AUTOSAR XML (schema 4-2-2)
package /STELLANTIS/EPT/ASWCs
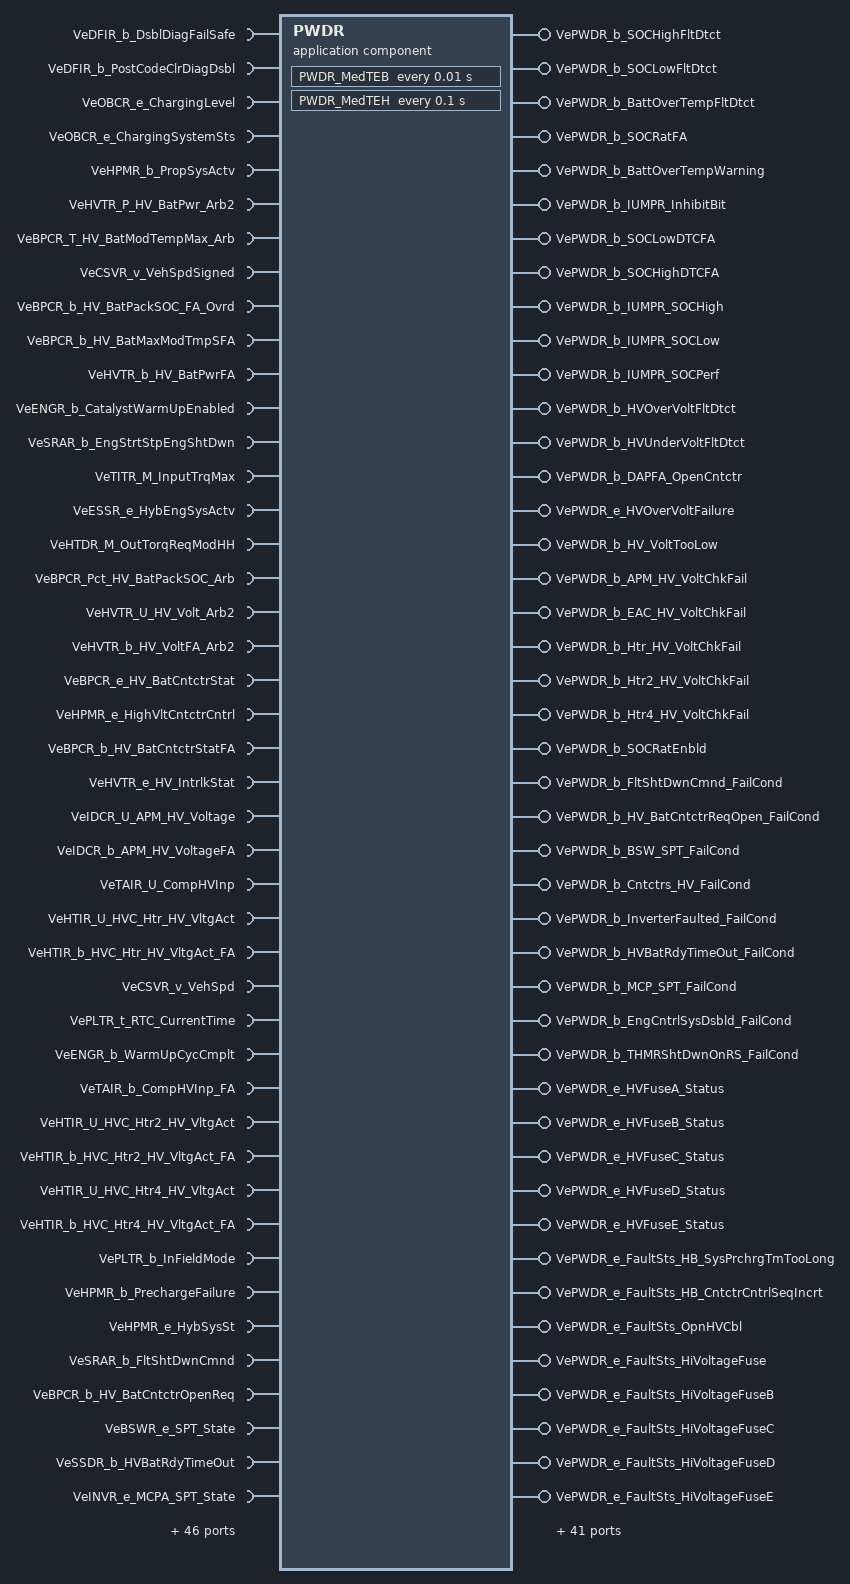
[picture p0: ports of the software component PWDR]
  application sw component type PWDR
    59 x require port:
      VeDFIR_b_DsblDiagFailSafe: nonqueued-receiver-com-spec{data-element=Value, init-value=0}, required-interface=VeDFIR_b_DsblDiagFailSafe
      VeDFIR_b_PostCodeClrDiagDsbl: nonqueued-receiver-com-spec{data-element=Value, init-value=0}, required-interface=VeDFIR_b_PostCodeClrDiagDsbl
      VeOBCR_e_ChargingLevel: nonqueued-receiver-com-spec{data-element=Value, init-value=CeOBCR_e_ChargingLvlDefault}, required-interface=VeOBCR_e_ChargingLevel
      VeOBCR_e_ChargingSystemSts: nonqueued-receiver-com-spec{data-element=Value, init-value=CeOBCR_e_NotCharging}, required-interface=VeOBCR_e_ChargingSystemSts
      VeHPMR_b_PropSysActv: nonqueued-receiver-com-spec{data-element=Value, init-value=0}, required-interface=VeHPMR_b_PropSysActv
      VeHVTR_P_HV_BatPwr_Arb2: nonqueued-receiver-com-spec{data-element=Value, init-value=0}, required-interface=VeHVTR_P_HV_BatPwr_Arb2
      VeBPCR_T_HV_BatModTempMax_Arb: nonqueued-receiver-com-spec{data-element=Value, init-value=0}, required-interface=VeBPCR_T_HV_BatModTempMax_Arb
      VeCSVR_v_VehSpdSigned: nonqueued-receiver-com-spec{data-element=Value, init-value=0}, required-interface=VeCSVR_v_VehSpdSigned
      VeBPCR_b_HV_BatPackSOC_FA_Ovrd: nonqueued-receiver-com-spec{data-element=Value, init-value=0}, required-interface=VeBPCR_b_HV_BatPackSOC_FA_Ovrd
      VeBPCR_b_HV_BatMaxModTmpSFA: nonqueued-receiver-com-spec{data-element=Value, init-value=0}, required-interface=VeBPCR_b_HV_BatMaxModTmpSFA
      VeHVTR_b_HV_BatPwrFA: nonqueued-receiver-com-spec{data-element=Value, init-value=0}, required-interface=VeHVTR_b_HV_BatPwrFA
      VeENGR_b_CatalystWarmUpEnabled: nonqueued-receiver-com-spec{data-element=Value, init-value=0}, required-interface=VeENGR_b_CatalystWarmUpEnabled
      VeSRAR_b_EngStrtStpEngShtDwn: nonqueued-receiver-com-spec{data-element=Value, init-value=0}, required-interface=VeSRAR_b_EngStrtStpEngShtDwn
      VeTITR_M_InputTrqMax: nonqueued-receiver-com-spec{data-element=Value, init-value=0}, required-interface=VeTITR_M_InputTrqMax
      VeESSR_e_HybEngSysActv: nonqueued-receiver-com-spec{data-element=Value, init-value=CeESSR_e_HybEngDisabled}, required-interface=VeESSR_e_HybEngSysActv
      VeHTDR_M_OutTorqReqModHH: nonqueued-receiver-com-spec{data-element=Value, init-value=0}, required-interface=VeHTDR_M_OutTorqReqModHH
      VeBPCR_Pct_HV_BatPackSOC_Arb: nonqueued-receiver-com-spec{data-element=Value, init-value=0}, required-interface=VeBPCR_Pct_HV_BatPackSOC_Arb
      VeHVTR_U_HV_Volt_Arb2: nonqueued-receiver-com-spec{data-element=Value, init-value=0}, required-interface=VeHVTR_U_HV_Volt_Arb2
      VeHVTR_b_HV_VoltFA_Arb2: nonqueued-receiver-com-spec{data-element=Value, init-value=0}, required-interface=VeHVTR_b_HV_VoltFA_Arb2
      VeBPCR_e_HV_BatCntctrStat: nonqueued-receiver-com-spec{data-element=Value, init-value=CeHVTR_e_Open}, required-interface=VeBPCR_e_HV_BatCntctrStat
      VeHPMR_e_HighVltCntctrCntrl: nonqueued-receiver-com-spec{data-element=Value, init-value=CeHPMR_e_Open}, required-interface=VeHPMR_e_HighVltCntctrCntrl
      VeBPCR_b_HV_BatCntctrStatFA: variation-point={short-label=vpVeBPCR_b_HV_BatCntctrStatFA, sw-syscond=1}, nonqueued-receiver-com-spec{data-element=Value, init-value=0}, required-interface=VeBPCR_b_HV_BatCntctrStatFA
      VeHVTR_e_HV_IntrlkStat: variation-point={short-label=vpVeHVTR_e_HV_IntrlkStat, sw-syscond=1}, nonqueued-receiver-com-spec{data-element=Value, init-value=CeHVTR_e_IntrlkNotSourced}, required-interface=VeHVTR_e_HV_IntrlkStat
      VeIDCR_U_APM_HV_Voltage: variation-point={short-label=vpVeIDCR_U_APM_HV_Voltage, sw-syscond=1}, nonqueued-receiver-com-spec{data-element=Value, init-value=0}, required-interface=VeIDCR_U_APM_HV_Voltage
      VeIDCR_b_APM_HV_VoltageFA: variation-point={short-label=vpVeIDCR_b_APM_HV_VoltageFA, sw-syscond=1}, nonqueued-receiver-com-spec{data-element=Value, init-value=0}, required-interface=VeIDCR_b_APM_HV_VoltageFA
      VeTAIR_U_CompHVInp: variation-point={short-label=vpVeTAIR_U_CompHVInp, sw-syscond=1}, nonqueued-receiver-com-spec{data-element=Value, init-value=0}, required-interface=VeTAIR_U_CompHVInp
      VeHTIR_U_HVC_Htr_HV_VltgAct: variation-point={short-label=vpVeHTIR_U_HVC_Htr_HV_VltgAct, sw-syscond=1}, nonqueued-receiver-com-spec{data-element=Value, init-value=0}, required-interface=VeHTIR_U_HVC_Htr_HV_VltgAct
      VeHTIR_b_HVC_Htr_HV_VltgAct_FA: variation-point={short-label=vpVeHTIR_b_HVC_Htr_HV_VltgAct_FA, sw-syscond=1}, nonqueued-receiver-com-spec{data-element=Value, init-value=0}, required-interface=VeHTIR_b_HVC_Htr_HV_VltgAct_FA
      VeCSVR_v_VehSpd: variation-point={short-label=vpVeCSVR_v_VehSpd, sw-syscond=1}, nonqueued-receiver-com-spec{data-element=Value, init-value=0}, required-interface=VeCSVR_v_VehSpd
      VePLTR_t_RTC_CurrentTime: variation-point={short-label=vpVePLTR_t_RTC_CurrentTime, sw-syscond=1}, nonqueued-receiver-com-spec{data-element=Value, init-value=0}, required-interface=VePLTR_t_RTC_CurrentTime
      VeENGR_b_WarmUpCycCmplt: variation-point={short-label=vpVeENGR_b_WarmUpCycCmplt, sw-syscond=1}, nonqueued-receiver-com-spec{data-element=Value, init-value=0}, required-interface=VeENGR_b_WarmUpCycCmplt
      VeTAIR_b_CompHVInp_FA: variation-point={short-label=vpVeTAIR_b_CompHVInp_FA, sw-syscond=1}, nonqueued-receiver-com-spec{data-element=Value, init-value=0}, required-interface=VeTAIR_b_CompHVInp_FA
      VeHTIR_U_HVC_Htr2_HV_VltgAct: variation-point={short-label=vpVeHTIR_U_HVC_Htr2_HV_VltgAct, sw-syscond=1}, nonqueued-receiver-com-spec{data-element=Value, init-value=0}, required-interface=VeHTIR_U_HVC_Htr2_HV_VltgAct
      VeHTIR_b_HVC_Htr2_HV_VltgAct_FA: variation-point={short-label=vpVeHTIR_b_HVC_Htr2_HV_VltgAct_FA, sw-syscond=1}, nonqueued-receiver-com-spec{data-element=Value, init-value=0}, required-interface=VeHTIR_b_HVC_Htr2_HV_VltgAct_FA
      VeHTIR_U_HVC_Htr4_HV_VltgAct: variation-point={short-label=vpVeHTIR_U_HVC_Htr4_HV_VltgAct, sw-syscond=1}, nonqueued-receiver-com-spec{data-element=Value, init-value=0}, required-interface=VeHTIR_U_HVC_Htr4_HV_VltgAct
      VeHTIR_b_HVC_Htr4_HV_VltgAct_FA: variation-point={short-label=vpVeHTIR_b_HVC_Htr4_HV_VltgAct_FA, sw-syscond=1}, nonqueued-receiver-com-spec{data-element=Value, init-value=0}, required-interface=VeHTIR_b_HVC_Htr4_HV_VltgAct_FA
      VePLTR_b_InFieldMode: nonqueued-receiver-com-spec{data-element=Value, init-value=0}, required-interface=VePLTR_b_InFieldMode
      VeHPMR_b_PrechargeFailure: nonqueued-receiver-com-spec{data-element=Value, init-value=0}, required-interface=VeHPMR_b_PrechargeFailure
      VeHPMR_e_HybSysSt: nonqueued-receiver-com-spec{data-element=Value, init-value=CeHPMR_e_POWERUP}, required-interface=VeHPMR_e_HybSysSt
      VeSRAR_b_FltShtDwnCmnd: nonqueued-receiver-com-spec{data-element=Value, init-value=0}, required-interface=VeSRAR_b_FltShtDwnCmnd
      VeBPCR_b_HV_BatCntctrOpenReq: nonqueued-receiver-com-spec{data-element=Value, init-value=0}, required-interface=VeBPCR_b_HV_BatCntctrOpenReq
      VeBSWR_e_SPT_State: nonqueued-receiver-com-spec{data-element=Value, init-value=CeINVR_e_Pending_SPT}, required-interface=VeBSWR_e_SPT_State
      VeSSDR_b_HVBatRdyTimeOut: nonqueued-receiver-com-spec{data-element=Value, init-value=0}, required-interface=VeSSDR_b_HVBatRdyTimeOut
      VeINVR_e_MCPA_SPT_State: nonqueued-receiver-com-spec{data-element=Value, init-value=CeINVR_e_Pending_SPT}, required-interface=VeINVR_e_MCPA_SPT_State
      VeINVR_e_MCPB_SPT_State: nonqueued-receiver-com-spec{data-element=Value, init-value=CeINVR_e_Pending_SPT}, required-interface=VeINVR_e_MCPB_SPT_State
      VeHPMR_b_MCP_SPT_Timeout: nonqueued-receiver-com-spec{data-element=Value, init-value=0}, required-interface=VeHPMR_b_MCP_SPT_Timeout
      VeSSDR_b_DsblPrplsnSysArb_Out: nonqueued-receiver-com-spec{data-element=Value, init-value=0}, required-interface=VeSSDR_b_DsblPrplsnSysArb_Out
      VeHPMR_b_InverterFaultedOut: nonqueued-receiver-com-spec{data-element=Value, init-value=0}, required-interface=VeHPMR_b_InverterFaultedOut
      VeHVTR_e_HV_IntrnlIntrlkStat: variation-point={short-label=vpVeHVTR_e_HV_IntrnlIntrlkStat, sw-syscond=1}, nonqueued-receiver-com-spec{data-element=Value, init-value=CeBPCR_e_HVBatIntrlkSNA}, required-interface=VeHVTR_e_HV_IntrnlIntrlkStat
      VeDFIR_b_IsDiagGlobalConditionsValid: nonqueued-receiver-com-spec{data-element=Value, init-value=0}, required-interface=VeDFIR_b_IsDiagGlobalConditionsValid
      VeDMAB_y_StatusByte_LosCommBECM_A_CANC11: nonqueued-receiver-com-spec{data-element=Value, init-value=0}, required-interface=VeDMAB_y_StatusByte_LosCommBECM_A_CANC11
      VeDMAB_y_StatusByte_LosCommBECM_A: nonqueued-receiver-com-spec{data-element=Value, init-value=0}, required-interface=VeDMAB_y_StatusByte_LosCommBECM_A
      VeDCAB_e_Routine_RC1300_HVOpnCblReset_Op: nonqueued-receiver-com-spec{data-element=Value, init-value=CeDCAB_e_Routine_NOP}, required-interface=VeDCAB_e_Routine_RC1300_HVOpnCblReset_Op
      VeDMAB_y_StatusByte_HB_BattSOC_Hi: nonqueued-receiver-com-spec{data-element=Value, init-value=0}, required-interface=VeDMAB_y_StatusByte_HB_BattSOC_Hi
      VeDMAB_y_StatusByte_HB_BattSOC_Lo: nonqueued-receiver-com-spec{data-element=Value, init-value=0}, required-interface=VeDMAB_y_StatusByte_HB_BattSOC_Lo
      VeDMAB_y_StatusByte_HB_Ovrtemp: nonqueued-receiver-com-spec{data-element=Value, init-value=0}, required-interface=VeDMAB_y_StatusByte_HB_Ovrtemp
      VeDMAB_y_StatusByte_BPCM_P1A26: nonqueued-receiver-com-spec{data-element=Value, init-value=0}, required-interface=VeDMAB_y_StatusByte_BPCM_P1A26
      VeDMAB_y_StatusByte_HVILCkt: variation-point={short-label=vpVeDMAB_y_StatusByte_HVILCkt, sw-syscond=1}, nonqueued-receiver-com-spec{data-element=Value, init-value=0}, required-interface=VeDMAB_y_StatusByte_HVILCkt
      VeDMAB_y_StatusByte_OpnHVCbl: variation-point={short-label=vpVeDMAB_y_StatusByte_OpnHVCbl, sw-syscond=1}, nonqueued-receiver-com-spec{data-element=Value, init-value=0}, required-interface=VeDMAB_y_StatusByte_OpnHVCbl
    55 x provide port:
      VePWDR_b_SOCHighFltDtct: nonqueued-sender-com-spec{data-element=Value, init-value=0}, provided-interface=VePWDR_b_SOCHighFltDtct
      VePWDR_b_SOCLowFltDtct: nonqueued-sender-com-spec{data-element=Value, init-value=0}, provided-interface=VePWDR_b_SOCLowFltDtct
      VePWDR_b_BattOverTempFltDtct: nonqueued-sender-com-spec{data-element=Value, init-value=0}, provided-interface=VePWDR_b_BattOverTempFltDtct
      VePWDR_b_SOCRatFA: nonqueued-sender-com-spec{data-element=Value, init-value=0}, provided-interface=VePWDR_b_SOCRatFA
      VePWDR_b_BattOverTempWarning: nonqueued-sender-com-spec{data-element=Value, init-value=0}, provided-interface=VePWDR_b_BattOverTempWarning
      VePWDR_b_IUMPR_InhibitBit: nonqueued-sender-com-spec{data-element=Value, init-value=0}, provided-interface=VePWDR_b_IUMPR_InhibitBit
      VePWDR_b_SOCLowDTCFA: nonqueued-sender-com-spec{data-element=Value, init-value=0}, provided-interface=VePWDR_b_SOCLowDTCFA
      VePWDR_b_SOCHighDTCFA: nonqueued-sender-com-spec{data-element=Value, init-value=0}, provided-interface=VePWDR_b_SOCHighDTCFA
      VePWDR_b_IUMPR_SOCHigh: nonqueued-sender-com-spec{data-element=Value, init-value=0}, provided-interface=VePWDR_b_IUMPR_SOCHigh
      VePWDR_b_IUMPR_SOCLow: nonqueued-sender-com-spec{data-element=Value, init-value=0}, provided-interface=VePWDR_b_IUMPR_SOCLow
      VePWDR_b_IUMPR_SOCPerf: nonqueued-sender-com-spec{data-element=Value, init-value=0}, provided-interface=VePWDR_b_IUMPR_SOCPerf
      VePWDR_b_HVOverVoltFltDtct: nonqueued-sender-com-spec{data-element=Value, init-value=0}, provided-interface=VePWDR_b_HVOverVoltFltDtct
      VePWDR_b_HVUnderVoltFltDtct: nonqueued-sender-com-spec{data-element=Value, init-value=0}, provided-interface=VePWDR_b_HVUnderVoltFltDtct
      VePWDR_b_DAPFA_OpenCntctr: nonqueued-sender-com-spec{data-element=Value, init-value=0}, provided-interface=VePWDR_b_DAPFA_OpenCntctr
      VePWDR_e_HVOverVoltFailure: nonqueued-sender-com-spec{data-element=Value, init-value=CeHVTR_e_HVOverVoltPass}, provided-interface=VePWDR_e_HVOverVoltFailure
      VePWDR_b_HV_VoltTooLow: nonqueued-sender-com-spec{data-element=Value, init-value=0}, provided-interface=VePWDR_b_HV_VoltTooLow
      VePWDR_b_APM_HV_VoltChkFail: nonqueued-sender-com-spec{data-element=Value, init-value=0}, provided-interface=VePWDR_b_APM_HV_VoltChkFail
      VePWDR_b_EAC_HV_VoltChkFail: nonqueued-sender-com-spec{data-element=Value, init-value=0}, provided-interface=VePWDR_b_EAC_HV_VoltChkFail
      VePWDR_b_Htr_HV_VoltChkFail: nonqueued-sender-com-spec{data-element=Value, init-value=0}, provided-interface=VePWDR_b_Htr_HV_VoltChkFail
      VePWDR_b_Htr2_HV_VoltChkFail: nonqueued-sender-com-spec{data-element=Value, init-value=0}, provided-interface=VePWDR_b_Htr2_HV_VoltChkFail
      VePWDR_b_Htr4_HV_VoltChkFail: nonqueued-sender-com-spec{data-element=Value, init-value=0}, provided-interface=VePWDR_b_Htr4_HV_VoltChkFail
      VePWDR_b_SOCRatEnbld: nonqueued-sender-com-spec{data-element=Value, init-value=0}, provided-interface=VePWDR_b_SOCRatEnbld
      VePWDR_b_FltShtDwnCmnd_FailCond: nonqueued-sender-com-spec{data-element=Value, init-value=0}, provided-interface=VePWDR_b_FltShtDwnCmnd_FailCond
      VePWDR_b_HV_BatCntctrReqOpen_FailCond: nonqueued-sender-com-spec{data-element=Value, init-value=0}, provided-interface=VePWDR_b_HV_BatCntctrReqOpen_FailCond
      VePWDR_b_BSW_SPT_FailCond: nonqueued-sender-com-spec{data-element=Value, init-value=0}, provided-interface=VePWDR_b_BSW_SPT_FailCond
      VePWDR_b_Cntctrs_HV_FailCond: nonqueued-sender-com-spec{data-element=Value, init-value=0}, provided-interface=VePWDR_b_Cntctrs_HV_FailCond
      VePWDR_b_InverterFaulted_FailCond: nonqueued-sender-com-spec{data-element=Value, init-value=0}, provided-interface=VePWDR_b_InverterFaulted_FailCond
      VePWDR_b_HVBatRdyTimeOut_FailCond: nonqueued-sender-com-spec{data-element=Value, init-value=0}, provided-interface=VePWDR_b_HVBatRdyTimeOut_FailCond
      VePWDR_b_MCP_SPT_FailCond: nonqueued-sender-com-spec{data-element=Value, init-value=0}, provided-interface=VePWDR_b_MCP_SPT_FailCond
      VePWDR_b_EngCntrlSysDsbld_FailCond: nonqueued-sender-com-spec{data-element=Value, init-value=0}, provided-interface=VePWDR_b_EngCntrlSysDsbld_FailCond
      VePWDR_b_THMRShtDwnOnRS_FailCond: nonqueued-sender-com-spec{data-element=Value, init-value=0}, provided-interface=VePWDR_b_THMRShtDwnOnRS_FailCond
      VePWDR_e_HVFuseA_Status: nonqueued-sender-com-spec{data-element=Value, init-value=CePWDR_e_FuseNotSupported}, provided-interface=VePWDR_e_HVFuseA_Status
      VePWDR_e_HVFuseB_Status: nonqueued-sender-com-spec{data-element=Value, init-value=CePWDR_e_FuseNotSupported}, provided-interface=VePWDR_e_HVFuseB_Status
      VePWDR_e_HVFuseC_Status: nonqueued-sender-com-spec{data-element=Value, init-value=CePWDR_e_FuseNotSupported}, provided-interface=VePWDR_e_HVFuseC_Status
      VePWDR_e_HVFuseD_Status: nonqueued-sender-com-spec{data-element=Value, init-value=CePWDR_e_FuseNotSupported}, provided-interface=VePWDR_e_HVFuseD_Status
      VePWDR_e_HVFuseE_Status: nonqueued-sender-com-spec{data-element=Value, init-value=CePWDR_e_FuseNotSupported}, provided-interface=VePWDR_e_HVFuseE_Status
      VePWDR_e_FaultSts_HB_SysPrchrgTmTooLong: nonqueued-sender-com-spec{data-element=Value, init-value=CeDFIB_e_Init}, provided-interface=VePWDR_e_FaultSts_HB_SysPrchrgTmTooLong
      VePWDR_e_FaultSts_HB_CntctrCntrlSeqIncrt: nonqueued-sender-com-spec{data-element=Value, init-value=CeDFIB_e_Init}, provided-interface=VePWDR_e_FaultSts_HB_CntctrCntrlSeqIncrt
      VePWDR_e_FaultSts_OpnHVCbl: nonqueued-sender-com-spec{data-element=Value, init-value=CeDFIB_e_Init}, provided-interface=VePWDR_e_FaultSts_OpnHVCbl
      VePWDR_e_FaultSts_HiVoltageFuse: nonqueued-sender-com-spec{data-element=Value, init-value=CeDFIB_e_Init}, provided-interface=VePWDR_e_FaultSts_HiVoltageFuse
      VePWDR_e_FaultSts_HiVoltageFuseB: nonqueued-sender-com-spec{data-element=Value, init-value=CeDFIB_e_Init}, provided-interface=VePWDR_e_FaultSts_HiVoltageFuseB
      VePWDR_e_FaultSts_HiVoltageFuseC: nonqueued-sender-com-spec{data-element=Value, init-value=CeDFIB_e_Init}, provided-interface=VePWDR_e_FaultSts_HiVoltageFuseC
      VePWDR_e_FaultSts_HiVoltageFuseD: nonqueued-sender-com-spec{data-element=Value, init-value=CeDFIB_e_Init}, provided-interface=VePWDR_e_FaultSts_HiVoltageFuseD
      VePWDR_e_FaultSts_HiVoltageFuseE: nonqueued-sender-com-spec{data-element=Value, init-value=CeDFIB_e_Init}, provided-interface=VePWDR_e_FaultSts_HiVoltageFuseE
      VePWDR_e_FaultSts_HVILCkt: nonqueued-sender-com-spec{data-element=Value, init-value=CeDFIB_e_Init}, provided-interface=VePWDR_e_FaultSts_HVILCkt
      VePWDR_e_FaultSts_ConModImpWkupPerf: nonqueued-sender-com-spec{data-element=Value, init-value=CeDFIB_e_Init}, provided-interface=VePWDR_e_FaultSts_ConModImpWkupPerf
      VePWDR_e_FaultSts_HB_Ovrtemp: nonqueued-sender-com-spec{data-element=Value, init-value=CeDFIB_e_Init}, provided-interface=VePWDR_e_FaultSts_HB_Ovrtemp
      VePWDR_e_FaultSts_BPCM_P1A26: nonqueued-sender-com-spec{data-element=Value, init-value=CeDFIB_e_Init}, provided-interface=VePWDR_e_FaultSts_BPCM_P1A26
      VePWDR_e_FaultSts_HB_BattSOC_Hi: nonqueued-sender-com-spec{data-element=Value, init-value=CeDFIB_e_Init}, provided-interface=VePWDR_e_FaultSts_HB_BattSOC_Hi
      VePWDR_e_FaultSts_HB_BattSOC_Lo: nonqueued-sender-com-spec{data-element=Value, init-value=CeDFIB_e_Init}, provided-interface=VePWDR_e_FaultSts_HB_BattSOC_Lo
      VePWDR_b_RC1300_RoutineResults: nonqueued-sender-com-spec{data-element=Value, init-value=0}, provided-interface=VePWDR_b_RC1300_RoutineResults
      VePWDR_l_DAP_FA_DistTravld: nonqueued-sender-com-spec{data-element=Value, init-value=0}, provided-interface=VePWDR_l_DAP_FA_DistTravld
      VePWDR_Cnt_DAP_FA_KeyCylCnt: nonqueued-sender-com-spec{data-element=Value, init-value=0}, provided-interface=VePWDR_Cnt_DAP_FA_KeyCylCnt
      VePWDR_t_DAP_FA_ElapsedTime: nonqueued-sender-com-spec{data-element=Value, init-value=0}, provided-interface=VePWDR_t_DAP_FA_ElapsedTime
      VePWDR_y_DID_B524: nonqueued-sender-com-spec{data-element=Value, init-value=0}, provided-interface=VePWDR_y_DID_B524
    30 x require port:
      EePWDR_l_DAP_FA_DistTravld_Rx: nv-require-com-spec{init-value=0, variable=EePWDR_l_DAP_FA_DistTravld}, required-interface=EePWDR_l_DAP_FA_DistTravld
      NePWDR_Cnt_HVFuseEMFOP_Rx: nv-require-com-spec{init-value=0, variable=NePWDR_Cnt_HVFuseEMFOP}, required-interface=NePWDR_Cnt_HVFuseEMFOP
      EePWDR_y_DID_B524_Rx: nv-require-com-spec{init-value=0, variable=EePWDR_y_DID_B524}, required-interface=EePWDR_y_DID_B524
      EePWDR_t_DAP_FA_InitTime_Rx: nv-require-com-spec{init-value=0, variable=EePWDR_t_DAP_FA_InitTime}, required-interface=EePWDR_t_DAP_FA_InitTime
      EePWDR_b_DAPFA_OpenCntctr_Rx: nv-require-com-spec{init-value=0, variable=EePWDR_b_DAPFA_OpenCntctr}, required-interface=EePWDR_b_DAPFA_OpenCntctr
      NePWDR_Cnt_HVDAPMFOP_Rx: nv-require-com-spec{init-value=0, variable=NePWDR_Cnt_HVDAPMFOP}, required-interface=NePWDR_Cnt_HVDAPMFOP
      EePWDR_Cnt_WarmupCycle_Rx: nv-require-com-spec{init-value=0, variable=EePWDR_Cnt_WarmupCycle}, required-interface=EePWDR_Cnt_WarmupCycle
      EePWDR_t_DAP_FA_ElapsedTime_Rx: nv-require-com-spec{init-value=0, variable=EePWDR_t_DAP_FA_ElapsedTime}, required-interface=EePWDR_t_DAP_FA_ElapsedTime
      NePWDR_Cnt_HVFuseAMFOP_Rx: nv-require-com-spec{init-value=0, variable=NePWDR_Cnt_HVFuseAMFOP}, required-interface=NePWDR_Cnt_HVFuseAMFOP
      EePWDR_Cnt_DAP_FA_KeyCylCnt_Rx: nv-require-com-spec{init-value=0, variable=EePWDR_Cnt_DAP_FA_KeyCylCnt}, required-interface=EePWDR_Cnt_DAP_FA_KeyCylCnt
      NePWDR_Cnt_HVFuseBMFOP_Rx: nv-require-com-spec{init-value=0, variable=NePWDR_Cnt_HVFuseBMFOP}, required-interface=NePWDR_Cnt_HVFuseBMFOP
      NePWDR_Cnt_HVFuseCMFOP_Rx: nv-require-com-spec{init-value=0, variable=NePWDR_Cnt_HVFuseCMFOP}, required-interface=NePWDR_Cnt_HVFuseCMFOP
      NePWDR_Cnt_HVFuseDMFOP_Rx: nv-require-com-spec{init-value=0, variable=NePWDR_Cnt_HVFuseDMFOP}, required-interface=NePWDR_Cnt_HVFuseDMFOP
      NePWDR_Cnt_BPCM_MFOP_Rx: nv-require-com-spec{init-value=0, variable=NePWDR_Cnt_BPCM_MFOP}, required-interface=NePWDR_Cnt_BPCM_MFOP
      NePWDR_Cnt_BattOverTempFailureMFOP_Rx: nv-require-com-spec{init-value=0, variable=NePWDR_Cnt_BattOverTempFailureMFOP}, required-interface=NePWDR_Cnt_BattOverTempFailureMFOP
      NePWDR_Cnt_HVILCkt_MFOP_Rx: nv-require-com-spec{init-value=0, variable=NePWDR_Cnt_HVILCkt_MFOP}, required-interface=NePWDR_Cnt_HVILCkt_MFOP
      NePWDR_Cnt_HVOverVoltFailureMFOP_Rx: nv-require-com-spec{init-value=0, variable=NePWDR_Cnt_HVOverVoltFailureMFOP}, required-interface=NePWDR_Cnt_HVOverVoltFailureMFOP
      NePWDR_Cnt_HVOverVoltFailureMSOF_Rx: nv-require-com-spec{init-value=0, variable=NePWDR_Cnt_HVOverVoltFailureMSOF}, required-interface=NePWDR_Cnt_HVOverVoltFailureMSOF
      NePWDR_Cnt_HVOverVoltWarnMFOP_Rx: nv-require-com-spec{init-value=0, variable=NePWDR_Cnt_HVOverVoltWarnMFOP}, required-interface=NePWDR_Cnt_HVOverVoltWarnMFOP
      NePWDR_Cnt_HVOverVoltWarnMSOF_Rx: nv-require-com-spec{init-value=0, variable=NePWDR_Cnt_HVOverVoltWarnMSOF}, required-interface=NePWDR_Cnt_HVOverVoltWarnMSOF
      NePWDR_Cnt_HVUnderVoltFailureMFOP_Rx: nv-require-com-spec{init-value=0, variable=NePWDR_Cnt_HVUnderVoltFailureMFOP}, required-interface=NePWDR_Cnt_HVUnderVoltFailureMFOP
      NePWDR_Cnt_HVUnderVoltFailureMSOF_Rx: nv-require-com-spec{init-value=0, variable=NePWDR_Cnt_HVUnderVoltFailureMSOF}, required-interface=NePWDR_Cnt_HVUnderVoltFailureMSOF
      NePWDR_Cnt_HVUnderVoltWarnMFOP_Rx: nv-require-com-spec{init-value=0, variable=NePWDR_Cnt_HVUnderVoltWarnMFOP}, required-interface=NePWDR_Cnt_HVUnderVoltWarnMFOP
      NePWDR_Cnt_HVUnderVoltWarnMSOF_Rx: nv-require-com-spec{init-value=0, variable=NePWDR_Cnt_HVUnderVoltWarnMSOF}, required-interface=NePWDR_Cnt_HVUnderVoltWarnMSOF
      NePWDR_Cnt_MsmtchLowFOP_Rx: nv-require-com-spec{init-value=0, variable=NePWDR_Cnt_MsmtchLowFOP}, required-interface=NePWDR_Cnt_MsmtchLowFOP
      NePWDR_Cnt_SOCHighFailureMFOP_Rx: nv-require-com-spec{init-value=0, variable=NePWDR_Cnt_SOCHighFailureMFOP}, required-interface=NePWDR_Cnt_SOCHighFailureMFOP
      NePWDR_Cnt_SOCHighWarnMFOP_Rx: nv-require-com-spec{init-value=0, variable=NePWDR_Cnt_SOCHighWarnMFOP}, required-interface=NePWDR_Cnt_SOCHighWarnMFOP
      NePWDR_Cnt_SOCLowFailureMFOP_Rx: nv-require-com-spec{init-value=0, variable=NePWDR_Cnt_SOCLowFailureMFOP}, required-interface=NePWDR_Cnt_SOCLowFailureMFOP
      NePWDR_Cnt_SOCLowWarnMFOP_Rx: nv-require-com-spec{init-value=0, variable=NePWDR_Cnt_SOCLowWarnMFOP}, required-interface=NePWDR_Cnt_SOCLowWarnMFOP
      NePWDR_Cnt_StuckHiFOP_Rx: nv-require-com-spec{init-value=0, variable=NePWDR_Cnt_StuckHiFOP}, required-interface=NePWDR_Cnt_StuckHiFOP
    30 x provide port:
      EePWDR_l_DAP_FA_DistTravld: nv-provide-com-spec{ram-block-init-value=0, variable=EePWDR_l_DAP_FA_DistTravld}, provided-interface=EePWDR_l_DAP_FA_DistTravld
      NePWDR_Cnt_HVFuseEMFOP: nv-provide-com-spec{ram-block-init-value=0, variable=NePWDR_Cnt_HVFuseEMFOP}, provided-interface=NePWDR_Cnt_HVFuseEMFOP
      EePWDR_y_DID_B524: nv-provide-com-spec{ram-block-init-value=0, variable=EePWDR_y_DID_B524}, provided-interface=EePWDR_y_DID_B524
      EePWDR_t_DAP_FA_InitTime: nv-provide-com-spec{ram-block-init-value=0, variable=EePWDR_t_DAP_FA_InitTime}, provided-interface=EePWDR_t_DAP_FA_InitTime
      EePWDR_b_DAPFA_OpenCntctr: nv-provide-com-spec{ram-block-init-value=0, variable=EePWDR_b_DAPFA_OpenCntctr}, provided-interface=EePWDR_b_DAPFA_OpenCntctr
      NePWDR_Cnt_HVDAPMFOP: nv-provide-com-spec{ram-block-init-value=0, variable=NePWDR_Cnt_HVDAPMFOP}, provided-interface=NePWDR_Cnt_HVDAPMFOP
      EePWDR_Cnt_WarmupCycle: nv-provide-com-spec{ram-block-init-value=0, variable=EePWDR_Cnt_WarmupCycle}, provided-interface=EePWDR_Cnt_WarmupCycle
      EePWDR_t_DAP_FA_ElapsedTime: nv-provide-com-spec{ram-block-init-value=0, variable=EePWDR_t_DAP_FA_ElapsedTime}, provided-interface=EePWDR_t_DAP_FA_ElapsedTime
      NePWDR_Cnt_HVFuseAMFOP: nv-provide-com-spec{ram-block-init-value=0, variable=NePWDR_Cnt_HVFuseAMFOP}, provided-interface=NePWDR_Cnt_HVFuseAMFOP
      EePWDR_Cnt_DAP_FA_KeyCylCnt: nv-provide-com-spec{ram-block-init-value=0, variable=EePWDR_Cnt_DAP_FA_KeyCylCnt}, provided-interface=EePWDR_Cnt_DAP_FA_KeyCylCnt
      NePWDR_Cnt_HVFuseBMFOP: nv-provide-com-spec{ram-block-init-value=0, variable=NePWDR_Cnt_HVFuseBMFOP}, provided-interface=NePWDR_Cnt_HVFuseBMFOP
      NePWDR_Cnt_HVFuseCMFOP: nv-provide-com-spec{ram-block-init-value=0, variable=NePWDR_Cnt_HVFuseCMFOP}, provided-interface=NePWDR_Cnt_HVFuseCMFOP
      NePWDR_Cnt_HVFuseDMFOP: nv-provide-com-spec{ram-block-init-value=0, variable=NePWDR_Cnt_HVFuseDMFOP}, provided-interface=NePWDR_Cnt_HVFuseDMFOP
      NePWDR_Cnt_BPCM_MFOP: nv-provide-com-spec{ram-block-init-value=0, variable=NePWDR_Cnt_BPCM_MFOP}, provided-interface=NePWDR_Cnt_BPCM_MFOP
      NePWDR_Cnt_BattOverTempFailureMFOP: nv-provide-com-spec{ram-block-init-value=0, variable=NePWDR_Cnt_BattOverTempFailureMFOP}, provided-interface=NePWDR_Cnt_BattOverTempFailureMFOP
      NePWDR_Cnt_HVILCkt_MFOP: nv-provide-com-spec{ram-block-init-value=0, variable=NePWDR_Cnt_HVILCkt_MFOP}, provided-interface=NePWDR_Cnt_HVILCkt_MFOP
      NePWDR_Cnt_HVOverVoltFailureMFOP: nv-provide-com-spec{ram-block-init-value=0, variable=NePWDR_Cnt_HVOverVoltFailureMFOP}, provided-interface=NePWDR_Cnt_HVOverVoltFailureMFOP
      NePWDR_Cnt_HVOverVoltFailureMSOF: nv-provide-com-spec{ram-block-init-value=0, variable=NePWDR_Cnt_HVOverVoltFailureMSOF}, provided-interface=NePWDR_Cnt_HVOverVoltFailureMSOF
      NePWDR_Cnt_HVOverVoltWarnMFOP: nv-provide-com-spec{ram-block-init-value=0, variable=NePWDR_Cnt_HVOverVoltWarnMFOP}, provided-interface=NePWDR_Cnt_HVOverVoltWarnMFOP
      NePWDR_Cnt_HVOverVoltWarnMSOF: nv-provide-com-spec{ram-block-init-value=0, variable=NePWDR_Cnt_HVOverVoltWarnMSOF}, provided-interface=NePWDR_Cnt_HVOverVoltWarnMSOF
      NePWDR_Cnt_HVUnderVoltFailureMFOP: nv-provide-com-spec{ram-block-init-value=0, variable=NePWDR_Cnt_HVUnderVoltFailureMFOP}, provided-interface=NePWDR_Cnt_HVUnderVoltFailureMFOP
      NePWDR_Cnt_HVUnderVoltFailureMSOF: nv-provide-com-spec{ram-block-init-value=0, variable=NePWDR_Cnt_HVUnderVoltFailureMSOF}, provided-interface=NePWDR_Cnt_HVUnderVoltFailureMSOF
      NePWDR_Cnt_HVUnderVoltWarnMFOP: nv-provide-com-spec{ram-block-init-value=0, variable=NePWDR_Cnt_HVUnderVoltWarnMFOP}, provided-interface=NePWDR_Cnt_HVUnderVoltWarnMFOP
      NePWDR_Cnt_HVUnderVoltWarnMSOF: nv-provide-com-spec{ram-block-init-value=0, variable=NePWDR_Cnt_HVUnderVoltWarnMSOF}, provided-interface=NePWDR_Cnt_HVUnderVoltWarnMSOF
      NePWDR_Cnt_MsmtchLowFOP: nv-provide-com-spec{ram-block-init-value=0, variable=NePWDR_Cnt_MsmtchLowFOP}, provided-interface=NePWDR_Cnt_MsmtchLowFOP
      NePWDR_Cnt_SOCHighFailureMFOP: nv-provide-com-spec{ram-block-init-value=0, variable=NePWDR_Cnt_SOCHighFailureMFOP}, provided-interface=NePWDR_Cnt_SOCHighFailureMFOP
      NePWDR_Cnt_SOCHighWarnMFOP: nv-provide-com-spec{ram-block-init-value=0, variable=NePWDR_Cnt_SOCHighWarnMFOP}, provided-interface=NePWDR_Cnt_SOCHighWarnMFOP
      NePWDR_Cnt_SOCLowFailureMFOP: nv-provide-com-spec{ram-block-init-value=0, variable=NePWDR_Cnt_SOCLowFailureMFOP}, provided-interface=NePWDR_Cnt_SOCLowFailureMFOP
      NePWDR_Cnt_SOCLowWarnMFOP: nv-provide-com-spec{ram-block-init-value=0, variable=NePWDR_Cnt_SOCLowWarnMFOP}, provided-interface=NePWDR_Cnt_SOCLowWarnMFOP
      NePWDR_Cnt_StuckHiFOP: nv-provide-com-spec{ram-block-init-value=0, variable=NePWDR_Cnt_StuckHiFOP}, provided-interface=NePWDR_Cnt_StuckHiFOP
    require port KeHPMR_t_BSWTimeout_SPT: parameter-require-com-spec{init-value=KeHPMR_t_BSWTimeout_SPT_KeHPMR_t_BSWTimeout_SPT:0.5, parameter=KeHPMR_t_BSWTimeout_SPT}, required-interface=KeHPMR_t_BSWTimeout_SPT
    behavior IB_PWDR: data-type-mapping=msADTtoIDTMapping, handle-termination-and-restart=NO-SUPPORT
      timing event Event_MedTEB: start-on-event=PWDR_MedTEB, period=0.01
      timing event Event_MedTEH: start-on-event=PWDR_MedTEH, period=0.1
      init event Event_PWDR_ac_Init: start-on-event=PWDR_ac_Init
      init event Event_PwrOn: start-on-event=PWDR_PwrOn
      init event Event_PwrOff: start-on-event=PWDR_PwrOff
      data received event Event_Routine_RC1300_HVOpnCblReset: start-on-event=Routine_RC1300_HVOpnCblReset, data=VeDCAB_e_Routine_RC1300_HVOpnCblReset_Op.Value
      explicit-inter-runnable-variables:
        data DAPFAOpenCntctrEEPROM_write_IRV: category=VALUE, sw-calibration-access=READ-ONLY, type=Boolean, init-value=0, variation-point={short-label=vpDAPFAOpenCntctrEEPROM_write_IRV, sw-syscond=1}
      6 x runnable:
        PWDR_ac_Init
          data-send-points:
            20 x access:
              OUT_VePWDR_e_HVOverVoltFailure_Value: accessed-variable=VePWDR_e_HVOverVoltFailure.Value
              OUT_VePWDR_e_HVFuseA_Status_Value: accessed-variable=VePWDR_e_HVFuseA_Status.Value
              OUT_VePWDR_e_HVFuseB_Status_Value: accessed-variable=VePWDR_e_HVFuseB_Status.Value
              OUT_VePWDR_e_HVFuseC_Status_Value: accessed-variable=VePWDR_e_HVFuseC_Status.Value
              OUT_VePWDR_e_HVFuseD_Status_Value: accessed-variable=VePWDR_e_HVFuseD_Status.Value
              OUT_VePWDR_e_HVFuseE_Status_Value: accessed-variable=VePWDR_e_HVFuseE_Status.Value
              OUT_VePWDR_e_FaultSts_HB_SysPrchrgTmTooLong_Value: accessed-variable=VePWDR_e_FaultSts_HB_SysPrchrgTmTooLong.Value
              OUT_VePWDR_e_FaultSts_HB_CntctrCntrlSeqIncrt_Value: accessed-variable=VePWDR_e_FaultSts_HB_CntctrCntrlSeqIncrt.Value
              OUT_VePWDR_e_FaultSts_OpnHVCbl_Value: accessed-variable=VePWDR_e_FaultSts_OpnHVCbl.Value
              OUT_VePWDR_e_FaultSts_HiVoltageFuse_Value: accessed-variable=VePWDR_e_FaultSts_HiVoltageFuse.Value
              OUT_VePWDR_e_FaultSts_HiVoltageFuseB_Value: accessed-variable=VePWDR_e_FaultSts_HiVoltageFuseB.Value
              OUT_VePWDR_e_FaultSts_HiVoltageFuseC_Value: accessed-variable=VePWDR_e_FaultSts_HiVoltageFuseC.Value
              OUT_VePWDR_e_FaultSts_HiVoltageFuseD_Value: accessed-variable=VePWDR_e_FaultSts_HiVoltageFuseD.Value
              OUT_VePWDR_e_FaultSts_HiVoltageFuseE_Value: accessed-variable=VePWDR_e_FaultSts_HiVoltageFuseE.Value
              OUT_VePWDR_e_FaultSts_HVILCkt_Value: accessed-variable=VePWDR_e_FaultSts_HVILCkt.Value
              OUT_VePWDR_e_FaultSts_ConModImpWkupPerf_Value: accessed-variable=VePWDR_e_FaultSts_ConModImpWkupPerf.Value
              OUT_VePWDR_e_FaultSts_HB_Ovrtemp_Value: accessed-variable=VePWDR_e_FaultSts_HB_Ovrtemp.Value
              OUT_VePWDR_e_FaultSts_BPCM_P1A26_Value: accessed-variable=VePWDR_e_FaultSts_BPCM_P1A26.Value
              OUT_VePWDR_e_FaultSts_HB_BattSOC_Hi_Value: accessed-variable=VePWDR_e_FaultSts_HB_BattSOC_Hi.Value
              OUT_VePWDR_e_FaultSts_HB_BattSOC_Lo_Value: accessed-variable=VePWDR_e_FaultSts_HB_BattSOC_Lo.Value
          written-local-variables:
            access WV_DAPFAOpenCntctrEEPROM_write_IRV: accessed-variable=DAPFAOpenCntctrEEPROM_write_IRV, variation-point={short-label=vpWV_DAPFAOpenCntctrEEPROM_write_IRV, sw-syscond=1}
        PWDR_PwrOn
          data-receive-point-by-arguments:
            30 x access:
              IN_EePWDR_Cnt_DAP_FA_KeyCylCnt_Rx_EePWDR_Cnt_DAP_FA_KeyCylCnt: accessed-variable=EePWDR_Cnt_DAP_FA_KeyCylCnt_Rx.EePWDR_Cnt_DAP_FA_KeyCylCnt
              IN_EePWDR_Cnt_WarmupCycle_Rx_EePWDR_Cnt_WarmupCycle: accessed-variable=EePWDR_Cnt_WarmupCycle_Rx.EePWDR_Cnt_WarmupCycle
              IN_EePWDR_b_DAPFA_OpenCntctr_Rx_EePWDR_b_DAPFA_OpenCntctr: accessed-variable=EePWDR_b_DAPFA_OpenCntctr_Rx.EePWDR_b_DAPFA_OpenCntctr
              IN_EePWDR_l_DAP_FA_DistTravld_Rx_EePWDR_l_DAP_FA_DistTravld: accessed-variable=EePWDR_l_DAP_FA_DistTravld_Rx.EePWDR_l_DAP_FA_DistTravld
              IN_EePWDR_t_DAP_FA_ElapsedTime_Rx_EePWDR_t_DAP_FA_ElapsedTime: accessed-variable=EePWDR_t_DAP_FA_ElapsedTime_Rx.EePWDR_t_DAP_FA_ElapsedTime
              IN_EePWDR_t_DAP_FA_InitTime_Rx_EePWDR_t_DAP_FA_InitTime: accessed-variable=EePWDR_t_DAP_FA_InitTime_Rx.EePWDR_t_DAP_FA_InitTime
              IN_EePWDR_y_DID_B524_Rx_EePWDR_y_DID_B524: accessed-variable=EePWDR_y_DID_B524_Rx.EePWDR_y_DID_B524
              IN_NePWDR_Cnt_BPCM_MFOP_Rx_NePWDR_Cnt_BPCM_MFOP: accessed-variable=NePWDR_Cnt_BPCM_MFOP_Rx.NePWDR_Cnt_BPCM_MFOP
              IN_NePWDR_Cnt_BattOverTempFailureMFOP_Rx_NePWDR_Cnt_BattOverTempFailureMFOP: accessed-variable=NePWDR_Cnt_BattOverTempFailureMFOP_Rx.NePWDR_Cnt_BattOverTempFailureMFOP
              IN_NePWDR_Cnt_HVDAPMFOP_Rx_NePWDR_Cnt_HVDAPMFOP: accessed-variable=NePWDR_Cnt_HVDAPMFOP_Rx.NePWDR_Cnt_HVDAPMFOP
              IN_NePWDR_Cnt_HVFuseAMFOP_Rx_NePWDR_Cnt_HVFuseAMFOP: accessed-variable=NePWDR_Cnt_HVFuseAMFOP_Rx.NePWDR_Cnt_HVFuseAMFOP
              IN_NePWDR_Cnt_HVFuseBMFOP_Rx_NePWDR_Cnt_HVFuseBMFOP: accessed-variable=NePWDR_Cnt_HVFuseBMFOP_Rx.NePWDR_Cnt_HVFuseBMFOP
              IN_NePWDR_Cnt_HVFuseCMFOP_Rx_NePWDR_Cnt_HVFuseCMFOP: accessed-variable=NePWDR_Cnt_HVFuseCMFOP_Rx.NePWDR_Cnt_HVFuseCMFOP
              IN_NePWDR_Cnt_HVFuseDMFOP_Rx_NePWDR_Cnt_HVFuseDMFOP: accessed-variable=NePWDR_Cnt_HVFuseDMFOP_Rx.NePWDR_Cnt_HVFuseDMFOP
              IN_NePWDR_Cnt_HVFuseEMFOP_Rx_NePWDR_Cnt_HVFuseEMFOP: accessed-variable=NePWDR_Cnt_HVFuseEMFOP_Rx.NePWDR_Cnt_HVFuseEMFOP
              IN_NePWDR_Cnt_HVILCkt_MFOP_Rx_NePWDR_Cnt_HVILCkt_MFOP: accessed-variable=NePWDR_Cnt_HVILCkt_MFOP_Rx.NePWDR_Cnt_HVILCkt_MFOP
              IN_NePWDR_Cnt_HVOverVoltFailureMFOP_Rx_NePWDR_Cnt_HVOverVoltFailureMFOP: accessed-variable=NePWDR_Cnt_HVOverVoltFailureMFOP_Rx.NePWDR_Cnt_HVOverVoltFailureMFOP
              IN_NePWDR_Cnt_HVOverVoltFailureMSOF_Rx_NePWDR_Cnt_HVOverVoltFailureMSOF: accessed-variable=NePWDR_Cnt_HVOverVoltFailureMSOF_Rx.NePWDR_Cnt_HVOverVoltFailureMSOF
              IN_NePWDR_Cnt_HVOverVoltWarnMFOP_Rx_NePWDR_Cnt_HVOverVoltWarnMFOP: accessed-variable=NePWDR_Cnt_HVOverVoltWarnMFOP_Rx.NePWDR_Cnt_HVOverVoltWarnMFOP
              IN_NePWDR_Cnt_HVOverVoltWarnMSOF_Rx_NePWDR_Cnt_HVOverVoltWarnMSOF: accessed-variable=NePWDR_Cnt_HVOverVoltWarnMSOF_Rx.NePWDR_Cnt_HVOverVoltWarnMSOF
              IN_NePWDR_Cnt_HVUnderVoltFailureMFOP_Rx_NePWDR_Cnt_HVUnderVoltFailureMFOP: accessed-variable=NePWDR_Cnt_HVUnderVoltFailureMFOP_Rx.NePWDR_Cnt_HVUnderVoltFailureMFOP
              IN_NePWDR_Cnt_HVUnderVoltFailureMSOF_Rx_NePWDR_Cnt_HVUnderVoltFailureMSOF: accessed-variable=NePWDR_Cnt_HVUnderVoltFailureMSOF_Rx.NePWDR_Cnt_HVUnderVoltFailureMSOF
              IN_NePWDR_Cnt_HVUnderVoltWarnMFOP_Rx_NePWDR_Cnt_HVUnderVoltWarnMFOP: accessed-variable=NePWDR_Cnt_HVUnderVoltWarnMFOP_Rx.NePWDR_Cnt_HVUnderVoltWarnMFOP
              IN_NePWDR_Cnt_HVUnderVoltWarnMSOF_Rx_NePWDR_Cnt_HVUnderVoltWarnMSOF: accessed-variable=NePWDR_Cnt_HVUnderVoltWarnMSOF_Rx.NePWDR_Cnt_HVUnderVoltWarnMSOF
              IN_NePWDR_Cnt_MsmtchLowFOP_Rx_NePWDR_Cnt_MsmtchLowFOP: accessed-variable=NePWDR_Cnt_MsmtchLowFOP_Rx.NePWDR_Cnt_MsmtchLowFOP
              IN_NePWDR_Cnt_SOCHighFailureMFOP_Rx_NePWDR_Cnt_SOCHighFailureMFOP: accessed-variable=NePWDR_Cnt_SOCHighFailureMFOP_Rx.NePWDR_Cnt_SOCHighFailureMFOP
              IN_NePWDR_Cnt_SOCHighWarnMFOP_Rx_NePWDR_Cnt_SOCHighWarnMFOP: accessed-variable=NePWDR_Cnt_SOCHighWarnMFOP_Rx.NePWDR_Cnt_SOCHighWarnMFOP
              IN_NePWDR_Cnt_SOCLowFailureMFOP_Rx_NePWDR_Cnt_SOCLowFailureMFOP: accessed-variable=NePWDR_Cnt_SOCLowFailureMFOP_Rx.NePWDR_Cnt_SOCLowFailureMFOP
              IN_NePWDR_Cnt_SOCLowWarnMFOP_Rx_NePWDR_Cnt_SOCLowWarnMFOP: accessed-variable=NePWDR_Cnt_SOCLowWarnMFOP_Rx.NePWDR_Cnt_SOCLowWarnMFOP
              IN_NePWDR_Cnt_StuckHiFOP_Rx_NePWDR_Cnt_StuckHiFOP: accessed-variable=NePWDR_Cnt_StuckHiFOP_Rx.NePWDR_Cnt_StuckHiFOP
          data-send-points:
            55 x access:
              OUT_VePWDR_b_SOCHighFltDtct_Value: accessed-variable=VePWDR_b_SOCHighFltDtct.Value
              OUT_VePWDR_b_SOCLowFltDtct_Value: accessed-variable=VePWDR_b_SOCLowFltDtct.Value
              OUT_VePWDR_b_BattOverTempFltDtct_Value: accessed-variable=VePWDR_b_BattOverTempFltDtct.Value
              OUT_VePWDR_b_SOCRatFA_Value: accessed-variable=VePWDR_b_SOCRatFA.Value
              OUT_VePWDR_b_BattOverTempWarning_Value: accessed-variable=VePWDR_b_BattOverTempWarning.Value
              OUT_VePWDR_b_IUMPR_InhibitBit_Value: accessed-variable=VePWDR_b_IUMPR_InhibitBit.Value
              OUT_VePWDR_b_SOCLowDTCFA_Value: accessed-variable=VePWDR_b_SOCLowDTCFA.Value
              OUT_VePWDR_b_SOCHighDTCFA_Value: accessed-variable=VePWDR_b_SOCHighDTCFA.Value
              OUT_VePWDR_b_IUMPR_SOCHigh_Value: accessed-variable=VePWDR_b_IUMPR_SOCHigh.Value
              OUT_VePWDR_b_IUMPR_SOCLow_Value: accessed-variable=VePWDR_b_IUMPR_SOCLow.Value
              OUT_VePWDR_b_IUMPR_SOCPerf_Value: accessed-variable=VePWDR_b_IUMPR_SOCPerf.Value
              OUT_VePWDR_b_HVOverVoltFltDtct_Value: accessed-variable=VePWDR_b_HVOverVoltFltDtct.Value
              OUT_VePWDR_b_HVUnderVoltFltDtct_Value: accessed-variable=VePWDR_b_HVUnderVoltFltDtct.Value
              OUT_VePWDR_b_DAPFA_OpenCntctr_Value: accessed-variable=VePWDR_b_DAPFA_OpenCntctr.Value
              OUT_VePWDR_e_HVOverVoltFailure_Value: accessed-variable=VePWDR_e_HVOverVoltFailure.Value
              OUT_VePWDR_b_HV_VoltTooLow_Value: accessed-variable=VePWDR_b_HV_VoltTooLow.Value
              OUT_VePWDR_b_APM_HV_VoltChkFail_Value: accessed-variable=VePWDR_b_APM_HV_VoltChkFail.Value
              OUT_VePWDR_b_EAC_HV_VoltChkFail_Value: accessed-variable=VePWDR_b_EAC_HV_VoltChkFail.Value
              OUT_VePWDR_b_Htr_HV_VoltChkFail_Value: accessed-variable=VePWDR_b_Htr_HV_VoltChkFail.Value
              OUT_VePWDR_b_Htr2_HV_VoltChkFail_Value: accessed-variable=VePWDR_b_Htr2_HV_VoltChkFail.Value
              OUT_VePWDR_b_Htr4_HV_VoltChkFail_Value: accessed-variable=VePWDR_b_Htr4_HV_VoltChkFail.Value
              OUT_VePWDR_b_SOCRatEnbld_Value: accessed-variable=VePWDR_b_SOCRatEnbld.Value
              OUT_VePWDR_b_FltShtDwnCmnd_FailCond_Value: accessed-variable=VePWDR_b_FltShtDwnCmnd_FailCond.Value
              OUT_VePWDR_b_HV_BatCntctrReqOpen_FailCond_Value: accessed-variable=VePWDR_b_HV_BatCntctrReqOpen_FailCond.Value
              OUT_VePWDR_b_BSW_SPT_FailCond_Value: accessed-variable=VePWDR_b_BSW_SPT_FailCond.Value
              OUT_VePWDR_b_Cntctrs_HV_FailCond_Value: accessed-variable=VePWDR_b_Cntctrs_HV_FailCond.Value
              OUT_VePWDR_b_InverterFaulted_FailCond_Value: accessed-variable=VePWDR_b_InverterFaulted_FailCond.Value
              OUT_VePWDR_b_HVBatRdyTimeOut_FailCond_Value: accessed-variable=VePWDR_b_HVBatRdyTimeOut_FailCond.Value
              OUT_VePWDR_b_MCP_SPT_FailCond_Value: accessed-variable=VePWDR_b_MCP_SPT_FailCond.Value
              OUT_VePWDR_b_EngCntrlSysDsbld_FailCond_Value: accessed-variable=VePWDR_b_EngCntrlSysDsbld_FailCond.Value
              OUT_VePWDR_b_THMRShtDwnOnRS_FailCond_Value: accessed-variable=VePWDR_b_THMRShtDwnOnRS_FailCond.Value
              OUT_VePWDR_e_HVFuseA_Status_Value: accessed-variable=VePWDR_e_HVFuseA_Status.Value
              OUT_VePWDR_e_HVFuseB_Status_Value: accessed-variable=VePWDR_e_HVFuseB_Status.Value
              OUT_VePWDR_e_HVFuseC_Status_Value: accessed-variable=VePWDR_e_HVFuseC_Status.Value
              OUT_VePWDR_e_HVFuseD_Status_Value: accessed-variable=VePWDR_e_HVFuseD_Status.Value
              OUT_VePWDR_e_HVFuseE_Status_Value: accessed-variable=VePWDR_e_HVFuseE_Status.Value
              OUT_VePWDR_e_FaultSts_HB_SysPrchrgTmTooLong_Value: accessed-variable=VePWDR_e_FaultSts_HB_SysPrchrgTmTooLong.Value
              OUT_VePWDR_e_FaultSts_HB_CntctrCntrlSeqIncrt_Value: accessed-variable=VePWDR_e_FaultSts_HB_CntctrCntrlSeqIncrt.Value
              OUT_VePWDR_e_FaultSts_OpnHVCbl_Value: accessed-variable=VePWDR_e_FaultSts_OpnHVCbl.Value
              OUT_VePWDR_e_FaultSts_HiVoltageFuse_Value: accessed-variable=VePWDR_e_FaultSts_HiVoltageFuse.Value
              OUT_VePWDR_e_FaultSts_HiVoltageFuseB_Value: accessed-variable=VePWDR_e_FaultSts_HiVoltageFuseB.Value
              OUT_VePWDR_e_FaultSts_HiVoltageFuseC_Value: accessed-variable=VePWDR_e_FaultSts_HiVoltageFuseC.Value
              OUT_VePWDR_e_FaultSts_HiVoltageFuseD_Value: accessed-variable=VePWDR_e_FaultSts_HiVoltageFuseD.Value
              OUT_VePWDR_e_FaultSts_HiVoltageFuseE_Value: accessed-variable=VePWDR_e_FaultSts_HiVoltageFuseE.Value
              OUT_VePWDR_e_FaultSts_HVILCkt_Value: accessed-variable=VePWDR_e_FaultSts_HVILCkt.Value
              OUT_VePWDR_e_FaultSts_ConModImpWkupPerf_Value: accessed-variable=VePWDR_e_FaultSts_ConModImpWkupPerf.Value
              OUT_VePWDR_e_FaultSts_HB_Ovrtemp_Value: accessed-variable=VePWDR_e_FaultSts_HB_Ovrtemp.Value
              OUT_VePWDR_e_FaultSts_BPCM_P1A26_Value: accessed-variable=VePWDR_e_FaultSts_BPCM_P1A26.Value
              OUT_VePWDR_e_FaultSts_HB_BattSOC_Hi_Value: accessed-variable=VePWDR_e_FaultSts_HB_BattSOC_Hi.Value
              OUT_VePWDR_e_FaultSts_HB_BattSOC_Lo_Value: accessed-variable=VePWDR_e_FaultSts_HB_BattSOC_Lo.Value
              OUT_VePWDR_b_RC1300_RoutineResults_Value: accessed-variable=VePWDR_b_RC1300_RoutineResults.Value
              OUT_VePWDR_l_DAP_FA_DistTravld_Value: accessed-variable=VePWDR_l_DAP_FA_DistTravld.Value
              OUT_VePWDR_Cnt_DAP_FA_KeyCylCnt_Value: accessed-variable=VePWDR_Cnt_DAP_FA_KeyCylCnt.Value
              OUT_VePWDR_t_DAP_FA_ElapsedTime_Value: accessed-variable=VePWDR_t_DAP_FA_ElapsedTime.Value
              OUT_VePWDR_y_DID_B524_Value: accessed-variable=VePWDR_y_DID_B524.Value
          written-local-variables:
            access WV_DAPFAOpenCntctrEEPROM_write_IRV: accessed-variable=DAPFAOpenCntctrEEPROM_write_IRV, variation-point={short-label=vpWV_DAPFAOpenCntctrEEPROM_write_IRV, sw-syscond=1}
        PWDR_MedTEB
          data-receive-point-by-arguments:
            40 x access:
              IN_VeBPCR_b_HV_BatCntctrOpenReq_Value: accessed-variable=VeBPCR_b_HV_BatCntctrOpenReq.Value
              IN_VeBPCR_b_HV_BatCntctrStatFA_Value: accessed-variable=VeBPCR_b_HV_BatCntctrStatFA.Value, variation-point={short-label=vpIN_VeBPCR_b_HV_BatCntctrStatFA_Value, sw-syscond=1}
              IN_VeBPCR_e_HV_BatCntctrStat_Value: accessed-variable=VeBPCR_e_HV_BatCntctrStat.Value
              IN_VeBSWR_e_SPT_State_Value: accessed-variable=VeBSWR_e_SPT_State.Value
              IN_VeCSVR_v_VehSpd_Value: accessed-variable=VeCSVR_v_VehSpd.Value, variation-point={short-label=vpIN_VeCSVR_v_VehSpd_Value, sw-syscond=1}
              IN_VeDFIR_b_DsblDiagFailSafe_Value: accessed-variable=VeDFIR_b_DsblDiagFailSafe.Value
              IN_VeDFIR_b_IsDiagGlobalConditionsValid_Value: accessed-variable=VeDFIR_b_IsDiagGlobalConditionsValid.Value
              IN_VeDFIR_b_PostCodeClrDiagDsbl_Value: accessed-variable=VeDFIR_b_PostCodeClrDiagDsbl.Value
              IN_VeDMAB_y_StatusByte_HVILCkt_Value: accessed-variable=VeDMAB_y_StatusByte_HVILCkt.Value, variation-point={short-label=vpIN_VeDMAB_y_StatusByte_HVILCkt_Value, sw-syscond=1}
              IN_VeDMAB_y_StatusByte_OpnHVCbl_Value: accessed-variable=VeDMAB_y_StatusByte_OpnHVCbl.Value, variation-point={short-label=vpIN_VeDMAB_y_StatusByte_OpnHVCbl_Value, sw-syscond=1}
              IN_VeENGR_b_WarmUpCycCmplt_Value: accessed-variable=VeENGR_b_WarmUpCycCmplt.Value, variation-point={short-label=vpIN_VeENGR_b_WarmUpCycCmplt_Value, sw-syscond=1}
              IN_VeESSR_e_HybEngSysActv_Value: accessed-variable=VeESSR_e_HybEngSysActv.Value
              IN_VeHPMR_b_InverterFaultedOut_Value: accessed-variable=VeHPMR_b_InverterFaultedOut.Value
              IN_VeHPMR_b_MCP_SPT_Timeout_Value: accessed-variable=VeHPMR_b_MCP_SPT_Timeout.Value
              IN_VeHPMR_b_PrechargeFailure_Value: accessed-variable=VeHPMR_b_PrechargeFailure.Value
              IN_VeHPMR_b_PropSysActv_Value: accessed-variable=VeHPMR_b_PropSysActv.Value
              IN_VeHPMR_e_HighVltCntctrCntrl_Value: accessed-variable=VeHPMR_e_HighVltCntctrCntrl.Value
              IN_VeHPMR_e_HybSysSt_Value: accessed-variable=VeHPMR_e_HybSysSt.Value
              IN_VeHTIR_U_HVC_Htr2_HV_VltgAct_Value: accessed-variable=VeHTIR_U_HVC_Htr2_HV_VltgAct.Value, variation-point={short-label=vpIN_VeHTIR_U_HVC_Htr2_HV_VltgAct_Value, sw-syscond=1}
              IN_VeHTIR_U_HVC_Htr4_HV_VltgAct_Value: accessed-variable=VeHTIR_U_HVC_Htr4_HV_VltgAct.Value, variation-point={short-label=vpIN_VeHTIR_U_HVC_Htr4_HV_VltgAct_Value, sw-syscond=1}
              IN_VeHTIR_U_HVC_Htr_HV_VltgAct_Value: accessed-variable=VeHTIR_U_HVC_Htr_HV_VltgAct.Value, variation-point={short-label=vpIN_VeHTIR_U_HVC_Htr_HV_VltgAct_Value, sw-syscond=1}
              IN_VeHTIR_b_HVC_Htr2_HV_VltgAct_FA_Value: accessed-variable=VeHTIR_b_HVC_Htr2_HV_VltgAct_FA.Value, variation-point={short-label=vpIN_VeHTIR_b_HVC_Htr2_HV_VltgAct_FA_Value, sw-syscond=1}
              IN_VeHTIR_b_HVC_Htr4_HV_VltgAct_FA_Value: accessed-variable=VeHTIR_b_HVC_Htr4_HV_VltgAct_FA.Value, variation-point={short-label=vpIN_VeHTIR_b_HVC_Htr4_HV_VltgAct_FA_Value, sw-syscond=1}
              IN_VeHTIR_b_HVC_Htr_HV_VltgAct_FA_Value: accessed-variable=VeHTIR_b_HVC_Htr_HV_VltgAct_FA.Value, variation-point={short-label=vpIN_VeHTIR_b_HVC_Htr_HV_VltgAct_FA_Value, sw-syscond=1}
              IN_VeHVTR_U_HV_Volt_Arb2_Value: accessed-variable=VeHVTR_U_HV_Volt_Arb2.Value
              IN_VeHVTR_b_HV_VoltFA_Arb2_Value: accessed-variable=VeHVTR_b_HV_VoltFA_Arb2.Value
              IN_VeHVTR_e_HV_IntrlkStat_Value: accessed-variable=VeHVTR_e_HV_IntrlkStat.Value, variation-point={short-label=vpIN_VeHVTR_e_HV_IntrlkStat_Value, sw-syscond=1}
              IN_VeHVTR_e_HV_IntrnlIntrlkStat_Value: accessed-variable=VeHVTR_e_HV_IntrnlIntrlkStat.Value, variation-point={short-label=vpIN_VeHVTR_e_HV_IntrnlIntrlkStat_Value, sw-syscond=1}
              IN_VeIDCR_U_APM_HV_Voltage_Value: accessed-variable=VeIDCR_U_APM_HV_Voltage.Value, variation-point={short-label=vpIN_VeIDCR_U_APM_HV_Voltage_Value, sw-syscond=1}
              IN_VeIDCR_b_APM_HV_VoltageFA_Value: accessed-variable=VeIDCR_b_APM_HV_VoltageFA.Value, variation-point={short-label=vpIN_VeIDCR_b_APM_HV_VoltageFA_Value, sw-syscond=1}
              IN_VeINVR_e_MCPA_SPT_State_Value: accessed-variable=VeINVR_e_MCPA_SPT_State.Value
              IN_VeINVR_e_MCPB_SPT_State_Value: accessed-variable=VeINVR_e_MCPB_SPT_State.Value
              IN_VeOBCR_e_ChargingLevel_Value: accessed-variable=VeOBCR_e_ChargingLevel.Value
              IN_VeOBCR_e_ChargingSystemSts_Value: accessed-variable=VeOBCR_e_ChargingSystemSts.Value
              IN_VePLTR_t_RTC_CurrentTime_Value: accessed-variable=VePLTR_t_RTC_CurrentTime.Value, variation-point={short-label=vpIN_VePLTR_t_RTC_CurrentTime_Value, sw-syscond=1}
              IN_VeSRAR_b_FltShtDwnCmnd_Value: accessed-variable=VeSRAR_b_FltShtDwnCmnd.Value
              IN_VeSSDR_b_DsblPrplsnSysArb_Out_Value: accessed-variable=VeSSDR_b_DsblPrplsnSysArb_Out.Value
              IN_VeSSDR_b_HVBatRdyTimeOut_Value: accessed-variable=VeSSDR_b_HVBatRdyTimeOut.Value
              IN_VeTAIR_U_CompHVInp_Value: accessed-variable=VeTAIR_U_CompHVInp.Value, variation-point={short-label=vpIN_VeTAIR_U_CompHVInp_Value, sw-syscond=1}
              IN_VeTAIR_b_CompHVInp_FA_Value: accessed-variable=VeTAIR_b_CompHVInp_FA.Value, variation-point={short-label=vpIN_VeTAIR_b_CompHVInp_FA_Value, sw-syscond=1}
          data-send-points:
            37 x access:
              OUT_VePWDR_b_HVOverVoltFltDtct_Value: accessed-variable=VePWDR_b_HVOverVoltFltDtct.Value
              OUT_VePWDR_b_HVUnderVoltFltDtct_Value: accessed-variable=VePWDR_b_HVUnderVoltFltDtct.Value
              OUT_VePWDR_b_DAPFA_OpenCntctr_Value: accessed-variable=VePWDR_b_DAPFA_OpenCntctr.Value
              OUT_VePWDR_e_HVOverVoltFailure_Value: accessed-variable=VePWDR_e_HVOverVoltFailure.Value
              OUT_VePWDR_b_HV_VoltTooLow_Value: accessed-variable=VePWDR_b_HV_VoltTooLow.Value
              OUT_VePWDR_b_APM_HV_VoltChkFail_Value: accessed-variable=VePWDR_b_APM_HV_VoltChkFail.Value
              OUT_VePWDR_b_EAC_HV_VoltChkFail_Value: accessed-variable=VePWDR_b_EAC_HV_VoltChkFail.Value
              OUT_VePWDR_b_Htr_HV_VoltChkFail_Value: accessed-variable=VePWDR_b_Htr_HV_VoltChkFail.Value
              OUT_VePWDR_b_Htr2_HV_VoltChkFail_Value: accessed-variable=VePWDR_b_Htr2_HV_VoltChkFail.Value
              OUT_VePWDR_b_Htr4_HV_VoltChkFail_Value: accessed-variable=VePWDR_b_Htr4_HV_VoltChkFail.Value
              OUT_VePWDR_e_HVFuseA_Status_Value: accessed-variable=VePWDR_e_HVFuseA_Status.Value
              OUT_VePWDR_e_HVFuseB_Status_Value: accessed-variable=VePWDR_e_HVFuseB_Status.Value
              OUT_VePWDR_e_HVFuseC_Status_Value: accessed-variable=VePWDR_e_HVFuseC_Status.Value
              OUT_VePWDR_e_HVFuseD_Status_Value: accessed-variable=VePWDR_e_HVFuseD_Status.Value
              OUT_VePWDR_e_HVFuseE_Status_Value: accessed-variable=VePWDR_e_HVFuseE_Status.Value
              OUT_VePWDR_b_FltShtDwnCmnd_FailCond_Value: accessed-variable=VePWDR_b_FltShtDwnCmnd_FailCond.Value
              OUT_VePWDR_b_HV_BatCntctrReqOpen_FailCond_Value: accessed-variable=VePWDR_b_HV_BatCntctrReqOpen_FailCond.Value
              OUT_VePWDR_b_BSW_SPT_FailCond_Value: accessed-variable=VePWDR_b_BSW_SPT_FailCond.Value
              OUT_VePWDR_b_Cntctrs_HV_FailCond_Value: accessed-variable=VePWDR_b_Cntctrs_HV_FailCond.Value
              OUT_VePWDR_b_InverterFaulted_FailCond_Value: accessed-variable=VePWDR_b_InverterFaulted_FailCond.Value
              OUT_VePWDR_b_HVBatRdyTimeOut_FailCond_Value: accessed-variable=VePWDR_b_HVBatRdyTimeOut_FailCond.Value
              OUT_VePWDR_b_MCP_SPT_FailCond_Value: accessed-variable=VePWDR_b_MCP_SPT_FailCond.Value
              OUT_VePWDR_b_EngCntrlSysDsbld_FailCond_Value: accessed-variable=VePWDR_b_EngCntrlSysDsbld_FailCond.Value
              OUT_VePWDR_b_THMRShtDwnOnRS_FailCond_Value: accessed-variable=VePWDR_b_THMRShtDwnOnRS_FailCond.Value
              OUT_VePWDR_e_FaultSts_HB_SysPrchrgTmTooLong_Value: accessed-variable=VePWDR_e_FaultSts_HB_SysPrchrgTmTooLong.Value
              OUT_VePWDR_e_FaultSts_HB_CntctrCntrlSeqIncrt_Value: accessed-variable=VePWDR_e_FaultSts_HB_CntctrCntrlSeqIncrt.Value
              OUT_VePWDR_e_FaultSts_OpnHVCbl_Value: accessed-variable=VePWDR_e_FaultSts_OpnHVCbl.Value
              OUT_VePWDR_e_FaultSts_HiVoltageFuse_Value: accessed-variable=VePWDR_e_FaultSts_HiVoltageFuse.Value
              OUT_VePWDR_e_FaultSts_HiVoltageFuseB_Value: accessed-variable=VePWDR_e_FaultSts_HiVoltageFuseB.Value
              OUT_VePWDR_e_FaultSts_HiVoltageFuseC_Value: accessed-variable=VePWDR_e_FaultSts_HiVoltageFuseC.Value
              OUT_VePWDR_e_FaultSts_HiVoltageFuseD_Value: accessed-variable=VePWDR_e_FaultSts_HiVoltageFuseD.Value
              OUT_VePWDR_e_FaultSts_HiVoltageFuseE_Value: accessed-variable=VePWDR_e_FaultSts_HiVoltageFuseE.Value
              OUT_VePWDR_e_FaultSts_HVILCkt_Value: accessed-variable=VePWDR_e_FaultSts_HVILCkt.Value
              OUT_VePWDR_l_DAP_FA_DistTravld_Value: accessed-variable=VePWDR_l_DAP_FA_DistTravld.Value
              OUT_VePWDR_Cnt_DAP_FA_KeyCylCnt_Value: accessed-variable=VePWDR_Cnt_DAP_FA_KeyCylCnt.Value
              OUT_VePWDR_t_DAP_FA_ElapsedTime_Value: accessed-variable=VePWDR_t_DAP_FA_ElapsedTime.Value
              OUT_VePWDR_y_DID_B524_Value: accessed-variable=VePWDR_y_DID_B524.Value
          parameter access CALPRM_KeHPMR_t_BSWTimeout_SPT_KeHPMR_t_BSWTimeout_SPT: accessed-parameter=KeHPMR_t_BSWTimeout_SPT.KeHPMR_t_BSWTimeout_SPT
          read-local-variables:
            access RV_DAPFAOpenCntctrEEPROM_write_IRV: accessed-variable=DAPFAOpenCntctrEEPROM_write_IRV, variation-point={short-label=vpRV_DAPFAOpenCntctrEEPROM_write_IRV, sw-syscond=1}
        PWDR_MedTEH
          data-receive-point-by-arguments:
            24 x access:
              IN_VeBPCR_Pct_HV_BatPackSOC_Arb_Value: accessed-variable=VeBPCR_Pct_HV_BatPackSOC_Arb.Value
              IN_VeBPCR_T_HV_BatModTempMax_Arb_Value: accessed-variable=VeBPCR_T_HV_BatModTempMax_Arb.Value
              IN_VeBPCR_b_HV_BatMaxModTmpSFA_Value: accessed-variable=VeBPCR_b_HV_BatMaxModTmpSFA.Value
              IN_VeBPCR_b_HV_BatPackSOC_FA_Ovrd_Value: accessed-variable=VeBPCR_b_HV_BatPackSOC_FA_Ovrd.Value
              IN_VeDFIR_b_DsblDiagFailSafe_Value: accessed-variable=VeDFIR_b_DsblDiagFailSafe.Value
              IN_VeDFIR_b_IsDiagGlobalConditionsValid_Value: accessed-variable=VeDFIR_b_IsDiagGlobalConditionsValid.Value
              IN_VeDFIR_b_PostCodeClrDiagDsbl_Value: accessed-variable=VeDFIR_b_PostCodeClrDiagDsbl.Value
              IN_VeDMAB_y_StatusByte_BPCM_P1A26_Value: accessed-variable=VeDMAB_y_StatusByte_BPCM_P1A26.Value
              IN_VeDMAB_y_StatusByte_HB_BattSOC_Hi_Value: accessed-variable=VeDMAB_y_StatusByte_HB_BattSOC_Hi.Value
              IN_VeDMAB_y_StatusByte_HB_BattSOC_Lo_Value: accessed-variable=VeDMAB_y_StatusByte_HB_BattSOC_Lo.Value
              IN_VeDMAB_y_StatusByte_HB_Ovrtemp_Value: accessed-variable=VeDMAB_y_StatusByte_HB_Ovrtemp.Value
              IN_VeDMAB_y_StatusByte_LosCommBECM_A_Value: accessed-variable=VeDMAB_y_StatusByte_LosCommBECM_A.Value
              IN_VeDMAB_y_StatusByte_LosCommBECM_A_CANC11_Value: accessed-variable=VeDMAB_y_StatusByte_LosCommBECM_A_CANC11.Value
              IN_VeENGR_b_CatalystWarmUpEnabled_Value: accessed-variable=VeENGR_b_CatalystWarmUpEnabled.Value
              IN_VeESSR_e_HybEngSysActv_Value: accessed-variable=VeESSR_e_HybEngSysActv.Value
              IN_VeHPMR_b_PropSysActv_Value: accessed-variable=VeHPMR_b_PropSysActv.Value
              IN_VeHTDR_M_OutTorqReqModHH_Value: accessed-variable=VeHTDR_M_OutTorqReqModHH.Value
              IN_VeHVTR_P_HV_BatPwr_Arb2_Value: accessed-variable=VeHVTR_P_HV_BatPwr_Arb2.Value
              IN_VeHVTR_b_HV_BatPwrFA_Value: accessed-variable=VeHVTR_b_HV_BatPwrFA.Value
              IN_VeOBCR_e_ChargingLevel_Value: accessed-variable=VeOBCR_e_ChargingLevel.Value
              IN_VeOBCR_e_ChargingSystemSts_Value: accessed-variable=VeOBCR_e_ChargingSystemSts.Value
              IN_VePLTR_b_InFieldMode_Value: accessed-variable=VePLTR_b_InFieldMode.Value
              IN_VeSRAR_b_EngStrtStpEngShtDwn_Value: accessed-variable=VeSRAR_b_EngStrtStpEngShtDwn.Value
              IN_VeTITR_M_InputTrqMax_Value: accessed-variable=VeTITR_M_InputTrqMax.Value
          data-send-points:
            16 x access:
              OUT_VePWDR_b_SOCHighFltDtct_Value: accessed-variable=VePWDR_b_SOCHighFltDtct.Value
              OUT_VePWDR_b_SOCLowFltDtct_Value: accessed-variable=VePWDR_b_SOCLowFltDtct.Value
              OUT_VePWDR_b_BattOverTempFltDtct_Value: accessed-variable=VePWDR_b_BattOverTempFltDtct.Value
              OUT_VePWDR_b_SOCRatFA_Value: accessed-variable=VePWDR_b_SOCRatFA.Value
              OUT_VePWDR_b_BattOverTempWarning_Value: accessed-variable=VePWDR_b_BattOverTempWarning.Value
              OUT_VePWDR_b_IUMPR_InhibitBit_Value: accessed-variable=VePWDR_b_IUMPR_InhibitBit.Value
              OUT_VePWDR_b_SOCLowDTCFA_Value: accessed-variable=VePWDR_b_SOCLowDTCFA.Value
              OUT_VePWDR_b_SOCHighDTCFA_Value: accessed-variable=VePWDR_b_SOCHighDTCFA.Value
              OUT_VePWDR_b_IUMPR_SOCHigh_Value: accessed-variable=VePWDR_b_IUMPR_SOCHigh.Value
              OUT_VePWDR_b_IUMPR_SOCLow_Value: accessed-variable=VePWDR_b_IUMPR_SOCLow.Value
              OUT_VePWDR_b_IUMPR_SOCPerf_Value: accessed-variable=VePWDR_b_IUMPR_SOCPerf.Value
              OUT_VePWDR_b_SOCRatEnbld_Value: accessed-variable=VePWDR_b_SOCRatEnbld.Value
              OUT_VePWDR_e_FaultSts_HB_Ovrtemp_Value: accessed-variable=VePWDR_e_FaultSts_HB_Ovrtemp.Value
              OUT_VePWDR_e_FaultSts_BPCM_P1A26_Value: accessed-variable=VePWDR_e_FaultSts_BPCM_P1A26.Value
              OUT_VePWDR_e_FaultSts_HB_BattSOC_Hi_Value: accessed-variable=VePWDR_e_FaultSts_HB_BattSOC_Hi.Value
              OUT_VePWDR_e_FaultSts_HB_BattSOC_Lo_Value: accessed-variable=VePWDR_e_FaultSts_HB_BattSOC_Lo.Value
        PWDR_PwrOff
          data-send-points:
            30 x access:
              OUT_EePWDR_l_DAP_FA_DistTravld_EePWDR_l_DAP_FA_DistTravld: accessed-variable=EePWDR_l_DAP_FA_DistTravld.EePWDR_l_DAP_FA_DistTravld
              OUT_NePWDR_Cnt_HVFuseEMFOP_NePWDR_Cnt_HVFuseEMFOP: accessed-variable=NePWDR_Cnt_HVFuseEMFOP.NePWDR_Cnt_HVFuseEMFOP
              OUT_EePWDR_y_DID_B524_EePWDR_y_DID_B524: accessed-variable=EePWDR_y_DID_B524.EePWDR_y_DID_B524
              OUT_EePWDR_t_DAP_FA_InitTime_EePWDR_t_DAP_FA_InitTime: accessed-variable=EePWDR_t_DAP_FA_InitTime.EePWDR_t_DAP_FA_InitTime
              OUT_EePWDR_b_DAPFA_OpenCntctr_EePWDR_b_DAPFA_OpenCntctr: accessed-variable=EePWDR_b_DAPFA_OpenCntctr.EePWDR_b_DAPFA_OpenCntctr
              OUT_NePWDR_Cnt_HVDAPMFOP_NePWDR_Cnt_HVDAPMFOP: accessed-variable=NePWDR_Cnt_HVDAPMFOP.NePWDR_Cnt_HVDAPMFOP
              OUT_EePWDR_Cnt_WarmupCycle_EePWDR_Cnt_WarmupCycle: accessed-variable=EePWDR_Cnt_WarmupCycle.EePWDR_Cnt_WarmupCycle
              OUT_EePWDR_t_DAP_FA_ElapsedTime_EePWDR_t_DAP_FA_ElapsedTime: accessed-variable=EePWDR_t_DAP_FA_ElapsedTime.EePWDR_t_DAP_FA_ElapsedTime
              OUT_NePWDR_Cnt_HVFuseAMFOP_NePWDR_Cnt_HVFuseAMFOP: accessed-variable=NePWDR_Cnt_HVFuseAMFOP.NePWDR_Cnt_HVFuseAMFOP
              OUT_EePWDR_Cnt_DAP_FA_KeyCylCnt_EePWDR_Cnt_DAP_FA_KeyCylCnt: accessed-variable=EePWDR_Cnt_DAP_FA_KeyCylCnt.EePWDR_Cnt_DAP_FA_KeyCylCnt
              OUT_NePWDR_Cnt_HVFuseBMFOP_NePWDR_Cnt_HVFuseBMFOP: accessed-variable=NePWDR_Cnt_HVFuseBMFOP.NePWDR_Cnt_HVFuseBMFOP
              OUT_NePWDR_Cnt_HVFuseCMFOP_NePWDR_Cnt_HVFuseCMFOP: accessed-variable=NePWDR_Cnt_HVFuseCMFOP.NePWDR_Cnt_HVFuseCMFOP
              OUT_NePWDR_Cnt_HVFuseDMFOP_NePWDR_Cnt_HVFuseDMFOP: accessed-variable=NePWDR_Cnt_HVFuseDMFOP.NePWDR_Cnt_HVFuseDMFOP
              OUT_NePWDR_Cnt_BPCM_MFOP_NePWDR_Cnt_BPCM_MFOP: accessed-variable=NePWDR_Cnt_BPCM_MFOP.NePWDR_Cnt_BPCM_MFOP
              OUT_NePWDR_Cnt_BattOverTempFailureMFOP_NePWDR_Cnt_BattOverTempFailureMFOP: accessed-variable=NePWDR_Cnt_BattOverTempFailureMFOP.NePWDR_Cnt_BattOverTempFailureMFOP
              OUT_NePWDR_Cnt_HVILCkt_MFOP_NePWDR_Cnt_HVILCkt_MFOP: accessed-variable=NePWDR_Cnt_HVILCkt_MFOP.NePWDR_Cnt_HVILCkt_MFOP
              OUT_NePWDR_Cnt_HVOverVoltFailureMFOP_NePWDR_Cnt_HVOverVoltFailureMFOP: accessed-variable=NePWDR_Cnt_HVOverVoltFailureMFOP.NePWDR_Cnt_HVOverVoltFailureMFOP
              OUT_NePWDR_Cnt_HVOverVoltFailureMSOF_NePWDR_Cnt_HVOverVoltFailureMSOF: accessed-variable=NePWDR_Cnt_HVOverVoltFailureMSOF.NePWDR_Cnt_HVOverVoltFailureMSOF
              OUT_NePWDR_Cnt_HVOverVoltWarnMFOP_NePWDR_Cnt_HVOverVoltWarnMFOP: accessed-variable=NePWDR_Cnt_HVOverVoltWarnMFOP.NePWDR_Cnt_HVOverVoltWarnMFOP
              OUT_NePWDR_Cnt_HVOverVoltWarnMSOF_NePWDR_Cnt_HVOverVoltWarnMSOF: accessed-variable=NePWDR_Cnt_HVOverVoltWarnMSOF.NePWDR_Cnt_HVOverVoltWarnMSOF
              OUT_NePWDR_Cnt_HVUnderVoltFailureMFOP_NePWDR_Cnt_HVUnderVoltFailureMFOP: accessed-variable=NePWDR_Cnt_HVUnderVoltFailureMFOP.NePWDR_Cnt_HVUnderVoltFailureMFOP
              OUT_NePWDR_Cnt_HVUnderVoltFailureMSOF_NePWDR_Cnt_HVUnderVoltFailureMSOF: accessed-variable=NePWDR_Cnt_HVUnderVoltFailureMSOF.NePWDR_Cnt_HVUnderVoltFailureMSOF
              OUT_NePWDR_Cnt_HVUnderVoltWarnMFOP_NePWDR_Cnt_HVUnderVoltWarnMFOP: accessed-variable=NePWDR_Cnt_HVUnderVoltWarnMFOP.NePWDR_Cnt_HVUnderVoltWarnMFOP
              OUT_NePWDR_Cnt_HVUnderVoltWarnMSOF_NePWDR_Cnt_HVUnderVoltWarnMSOF: accessed-variable=NePWDR_Cnt_HVUnderVoltWarnMSOF.NePWDR_Cnt_HVUnderVoltWarnMSOF
              OUT_NePWDR_Cnt_MsmtchLowFOP_NePWDR_Cnt_MsmtchLowFOP: accessed-variable=NePWDR_Cnt_MsmtchLowFOP.NePWDR_Cnt_MsmtchLowFOP
              OUT_NePWDR_Cnt_SOCHighFailureMFOP_NePWDR_Cnt_SOCHighFailureMFOP: accessed-variable=NePWDR_Cnt_SOCHighFailureMFOP.NePWDR_Cnt_SOCHighFailureMFOP
              OUT_NePWDR_Cnt_SOCHighWarnMFOP_NePWDR_Cnt_SOCHighWarnMFOP: accessed-variable=NePWDR_Cnt_SOCHighWarnMFOP.NePWDR_Cnt_SOCHighWarnMFOP
              OUT_NePWDR_Cnt_SOCLowFailureMFOP_NePWDR_Cnt_SOCLowFailureMFOP: accessed-variable=NePWDR_Cnt_SOCLowFailureMFOP.NePWDR_Cnt_SOCLowFailureMFOP
              OUT_NePWDR_Cnt_SOCLowWarnMFOP_NePWDR_Cnt_SOCLowWarnMFOP: accessed-variable=NePWDR_Cnt_SOCLowWarnMFOP.NePWDR_Cnt_SOCLowWarnMFOP
              OUT_NePWDR_Cnt_StuckHiFOP_NePWDR_Cnt_StuckHiFOP: accessed-variable=NePWDR_Cnt_StuckHiFOP.NePWDR_Cnt_StuckHiFOP
        Routine_RC1300_HVOpnCblReset
          data-receive-point-by-arguments:
            access IN_VeDCAB_e_Routine_RC1300_HVOpnCblReset_Op_Value: accessed-variable=VeDCAB_e_Routine_RC1300_HVOpnCblReset_Op.Value
          data-send-points:
            access OUT_VePWDR_b_RC1300_RoutineResults_Value: accessed-variable=VePWDR_b_RC1300_RoutineResults.Value
      7 x variation point proxy, all with category=CONDITION:
        Variant_PWDR_1: condition-access=0
        Variant_PWDR_2: condition-access=1
        Variant_PWDR_3: condition-access=1
        Variant_PWDR_{4..6}: condition-access=0
        Variant_PWDR_7: condition-access=1
